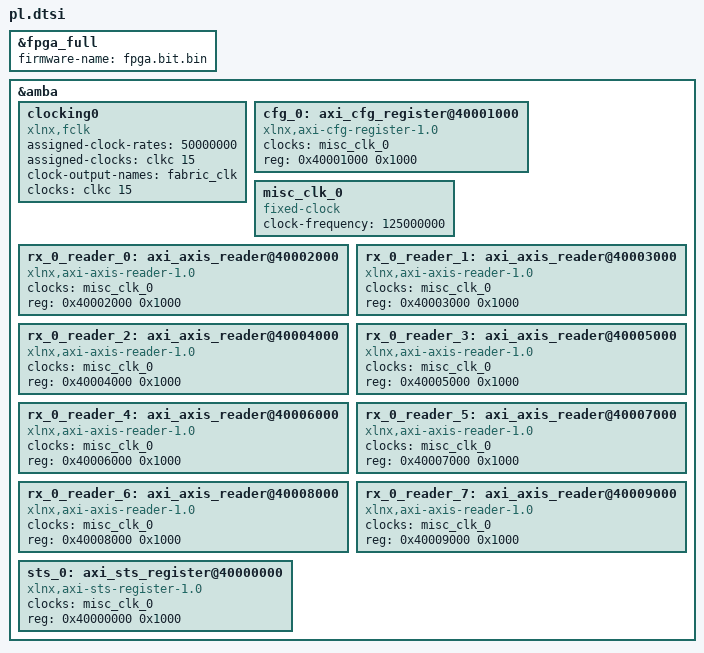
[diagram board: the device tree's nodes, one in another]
/*
 * CAUTION: This file is automatically generated by Xilinx.
 * Version:  
 * Today is: Thu May  4 12:11:48 2023
 */


/dts-v1/;
/plugin/;
/ {
	fragment@0 {
		target = <&fpga_full>;
		overlay0: __overlay__ {
			//#address-cells = <2>;
			//#size-cells = <2>;
			firmware-name = "fpga.bit.bin";
		};
	};
	fragment@1 {
		target = <&amba>;
		overlay1: __overlay__ {
			clocking0: clocking0 {
				#clock-cells = <0>;
				assigned-clock-rates = <50000000>;
				assigned-clocks = <&clkc 15>;
				clock-output-names = "fabric_clk";
				clocks = <&clkc 15>;
				compatible = "xlnx,fclk";
			};
		};
	};
	fragment@2 {
		target = <&amba>;
		overlay2: __overlay__ {
			//#address-cells = <1>;
			//#size-cells = <1>;
			cfg_0: axi_cfg_register@40001000 {
				clock-names = "aclk";
				clocks = <&misc_clk_0>;
				compatible = "xlnx,axi-cfg-register-1.0";
				reg = <0x40001000 0x1000>;
			};
			misc_clk_0: misc_clk_0 {
				#clock-cells = <0>;
				clock-frequency = <125000000>;
				compatible = "fixed-clock";
			};
			rx_0_reader_0: axi_axis_reader@40002000 {
				clock-names = "aclk";
				clocks = <&misc_clk_0>;
				compatible = "xlnx,axi-axis-reader-1.0";
				reg = <0x40002000 0x1000>;
			};
			rx_0_reader_1: axi_axis_reader@40003000 {
				clock-names = "aclk";
				clocks = <&misc_clk_0>;
				compatible = "xlnx,axi-axis-reader-1.0";
				reg = <0x40003000 0x1000>;
			};
			rx_0_reader_2: axi_axis_reader@40004000 {
				clock-names = "aclk";
				clocks = <&misc_clk_0>;
				compatible = "xlnx,axi-axis-reader-1.0";
				reg = <0x40004000 0x1000>;
			};
			rx_0_reader_3: axi_axis_reader@40005000 {
				clock-names = "aclk";
				clocks = <&misc_clk_0>;
				compatible = "xlnx,axi-axis-reader-1.0";
				reg = <0x40005000 0x1000>;
			};
			rx_0_reader_4: axi_axis_reader@40006000 {
				clock-names = "aclk";
				clocks = <&misc_clk_0>;
				compatible = "xlnx,axi-axis-reader-1.0";
				reg = <0x40006000 0x1000>;
			};
			rx_0_reader_5: axi_axis_reader@40007000 {
				clock-names = "aclk";
				clocks = <&misc_clk_0>;
				compatible = "xlnx,axi-axis-reader-1.0";
				reg = <0x40007000 0x1000>;
			};
			rx_0_reader_6: axi_axis_reader@40008000 {
				clock-names = "aclk";
				clocks = <&misc_clk_0>;
				compatible = "xlnx,axi-axis-reader-1.0";
				reg = <0x40008000 0x1000>;
			};
			rx_0_reader_7: axi_axis_reader@40009000 {
				clock-names = "aclk";
				clocks = <&misc_clk_0>;
				compatible = "xlnx,axi-axis-reader-1.0";
				reg = <0x40009000 0x1000>;
			};
			sts_0: axi_sts_register@40000000 {
				clock-names = "aclk";
				clocks = <&misc_clk_0>;
				compatible = "xlnx,axi-sts-register-1.0";
				reg = <0x40000000 0x1000>;
			};
		};
	};
};
